# srio register map
Vendor: Texas Instruments
Peripheral module from a debugger description file (folder Keystone2).
Registers are 32-bit, read-write, no defined reset value unless marked. A register's access mark holds for its fields unless they carry their own. Offsets are as the file gives them; lines under a group give offsets from that group; [hi:lo] are bit positions; {n}, {i} and the like mark numbered series; 'fields as' and 'values as' point back to an identical list; <NAME> marks a mode.

## SRIO
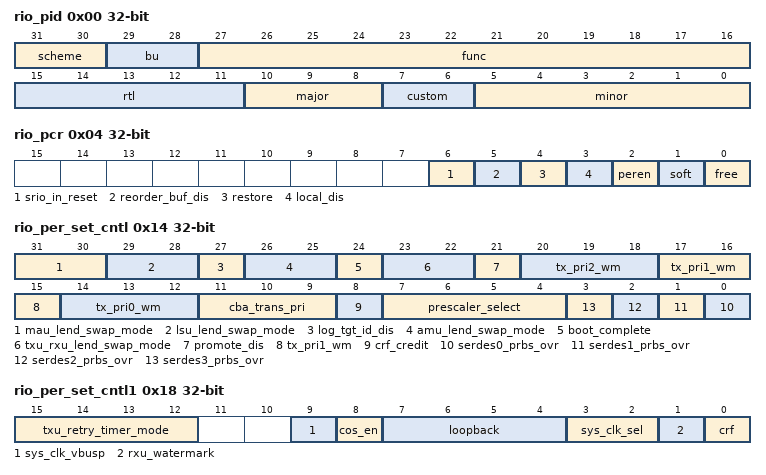
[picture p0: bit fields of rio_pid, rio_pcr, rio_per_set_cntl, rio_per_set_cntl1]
0x00 rio_pid ro
  [31:30] scheme — Reserved
  [29:28] bu — Business unit
  [27:16] func — Function ID
  [15:11] rtl — RTL revision
  [10:8] major — Major revision
  [7:6] custom
  [5:0] minor — Minor revision
0x04 rio_pcr access per field
  [6] srio_in_reset ro — SRIO has been given a reset isolation request, but has still not reached a stable state where it has started packet forwarding.
  [5] reorder_buf_dis rw — Write 1 disables the reorder bridge
  [4] restore rw — Write 1 clears local_dis
  [3] local_dis ro — local disable
  [2] peren rw — Peripheral enable
  [1] soft rw — Emulation control soft bit
  [0] free rw — Emulation control free bit
0x14 rio_per_set_cntl
  [31:30] mau_lend_swap_mode — MAU little endian swapping mode
  [29:28] lsu_lend_swap_mode — LSU little endian swapping mode
  [27] log_tgt_id_dis — Logical target ID disable mode
  [26:25] amu_lend_swap_mode — AMU little endian swapping mode
  [24] boot_complete — Controls ability to write any register during initialization
  [23:22] txu_rxu_lend_swap_mode — TXU/RXU little endian swap mode
  [21] promote_dis — Disable automatic promotion
  [20:18] tx_pri2_wm — Transmit credit threshold
  [17:15] tx_pri1_wm — Transmit credit threshold
  [14:12] tx_pri0_wm — Transmit credit threshold
  [11:9] cba_trans_pri — VBUS transaction priority
  [8] crf_credit
  [7:4] prescaler_select — VBUS frequency prescaler
  [n] serdes{n}_prbs_ovr (n=0..3) — SerDes PRBS override
0x18 rio_per_set_cntl1
  [15:12] txu_retry_timer_mode — Defines the total number of times the 14bit Rety Timer can expire before TXU will discard the retry request
  [9] sys_clk_vbusp — 0 = Use SYS_CLK_SEL to define the clock source SYS_CLK, 1 = Use vbusp_clk as the clock source for SYS_CLK
  [8] cos_en — Class of service enable
  [7:4] loopback — Loopback transmit data to receive on the same port
  [3:2] sys_clk_sel — SYS_CLK select
  [1] rxu_watermark
  [0] crf — 0=On a response, CRF is the same as the incoming request, 1=On a response, CFR is always 1
0x24 rio_gbl_en
  [0] en — global reset
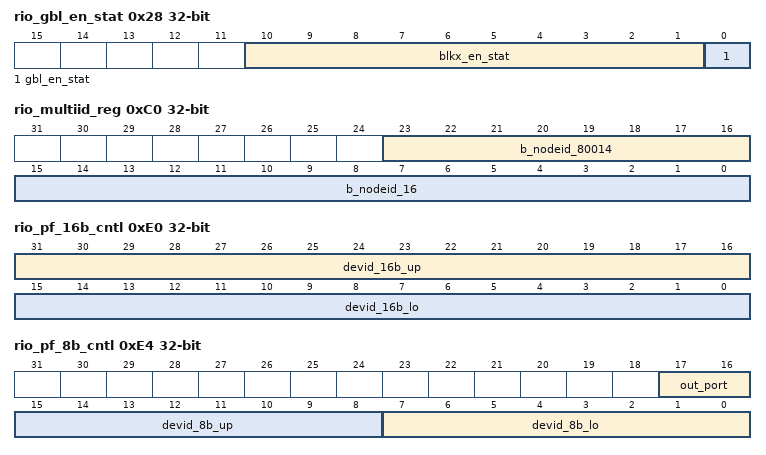
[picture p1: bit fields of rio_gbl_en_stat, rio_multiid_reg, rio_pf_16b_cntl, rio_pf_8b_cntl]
0x28 rio_gbl_en_stat ro
  [10:1] blkx_en_stat — Global enable status block 0..9
  [0] gbl_en_stat — Peripheral global enable status
0x2C rio_blk_en — (1 of 10, stride 8)
  [0] en — Block enable
0x30 rio_blk_en_stat ro — (1 of 10, stride 8)
  [0] en_status — Block enable status
0xC0 rio_multiid_reg — (1 of 8, stride 4)
  [23:16] b_nodeid_80014 — Secondary supported device ID check
  [15:0] b_nodeid_16 — Secondary supported device ID check
0xE0 rio_pf_16b_cntl — (1 of 8, stride 8)
  [31:16] devid_16b_up — Upper 16b DeviceID boundary
  [15:0] devid_16b_lo — Lower 16b DeviceID boundary
0xE4 rio_pf_8b_cntl — (1 of 8, stride 8)
  [17:16] out_port — Output port number for packets whose DestID falls within the 8b or 16b range for this table entry
  [15:8] devid_8b_up — Upper 8b DeviceID boundary
  [7:0] devid_8b_lo — Lower 8b DeviceID boundary
0x180 rio_doorbell_icsr — (1 of 4, stride 16)
  [15:0] rio_doorbell — ICS0 to ICS15
0x188 rio_doorbell_iccr wo — (1 of 4, stride 16)
  [15:0] rio_doorbell — ICC0 to ICC15
0x1C0 rio_lsu_icsr — (1 of 2, stride 16)
  [31:0] rio_lsu_icsr — LSU0 and LSU1 ICSR0-ICSR31
0x1C8 rio_lsu_iccr wo — (1 of 2, stride 16)
  [31:0] rio_lsu_iccr — LSU0 and LSU1 ICCR0-ICCR31
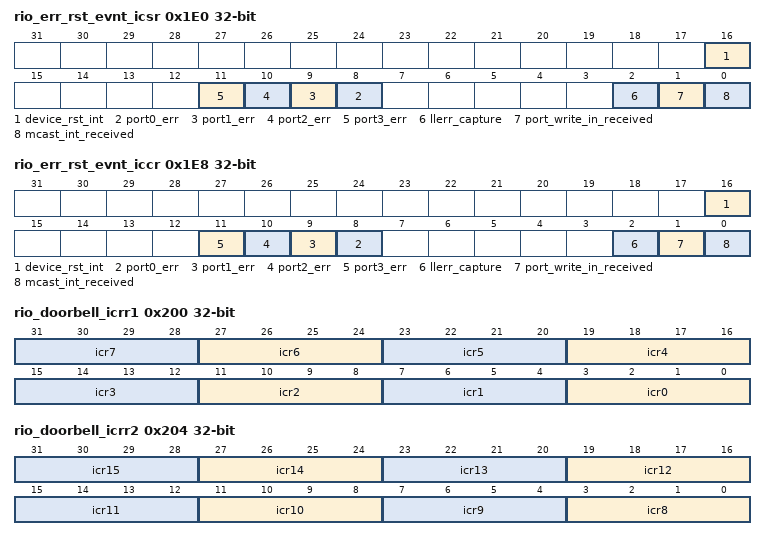
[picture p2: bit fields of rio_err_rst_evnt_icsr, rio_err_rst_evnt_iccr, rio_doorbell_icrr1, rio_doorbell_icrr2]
0x1E0 rio_err_rst_evnt_icsr
  [16] device_rst_int — Device reset interrupt from any port
  [n+8] port{n}_err (n=0..3) — Port {n} error
  [2] llerr_capture — Logical layer error management event capture
  [1] port_write_in_received — Port write in request received on any port
  [0] mcast_int_received — Multicast event control symbol interrupt received on any port
0x1E8 rio_err_rst_evnt_iccr wo
  fields as rio_err_rst_evnt_icsr
0x1F0 rio_amu_icsr
  [15:0] cprivid — CPRIVID0..15
0x1F8 rio_amu_iccr wo
  [15:0] cprivid — CPRIVID0..15
0x200 rio_doorbell_icrr1 — (1 of 4, stride 12)
  [4n+3:4n] icr{n} (n=0..7)
0x204 rio_doorbell_icrr2 — (1 of 4, stride 12)
  [4n-29:4n-32] icr{n} (n=8..15)
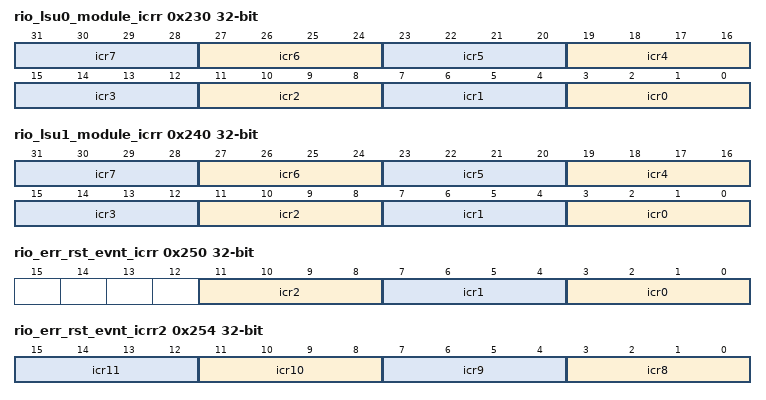
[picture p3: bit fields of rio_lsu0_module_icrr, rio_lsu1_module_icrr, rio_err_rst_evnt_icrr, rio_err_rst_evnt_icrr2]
0x230 rio_lsu0_module_icrr — (1 of 4, stride 4)
  [4n+3:4n] icr{n} (n=0..7)
0x240 rio_lsu1_module_icrr
  [4n+3:4n] icr{n} (n=0..7)
0x250 rio_err_rst_evnt_icrr
  [11:8] icr2, [7:4] icr1, [3:0] icr0
0x254 rio_err_rst_evnt_icrr2
  [4n-29:4n-32] icr{n} (n=8..11)
0x258 rio_err_rst_evnt_icrr3
  [3:0] icr16
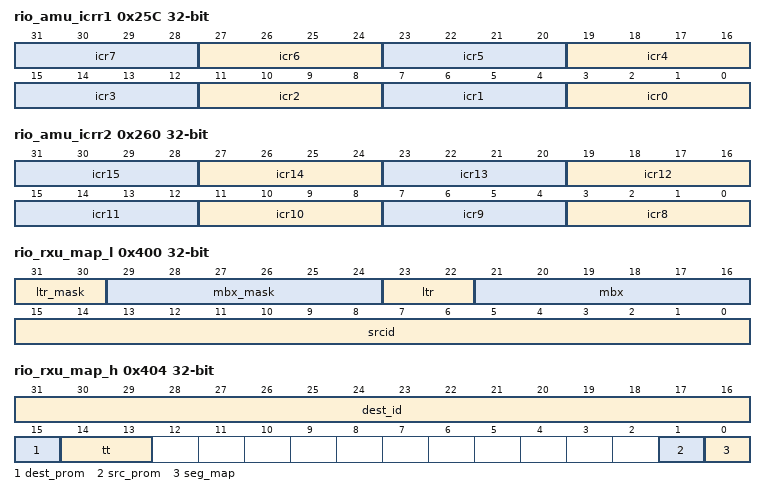
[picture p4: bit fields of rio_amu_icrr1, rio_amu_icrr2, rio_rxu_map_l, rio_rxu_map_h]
0x25C rio_amu_icrr1
  [4n+3:4n] icr{n} (n=0..7)
0x260 rio_amu_icrr2
  [4n-29:4n-32] icr{n} (n=8..15)
0x264 rio_interrupt_ctl
  [0] dbll_route — Doorbell interrupts routing table select
0x270 rio_intdst_decode ro — (1 of 24, stride 4)
  [31:0] isdr — Interrupt status decode bit 0..31
0x2D0 rio_intdst_rate_cnt — (1 of 16, stride 4)
  [31:0] count_down_value — INTDST rate control count down value
0x310 rio_intdst_rate_dis
  [15:0] raten_dis — Rate0..15 disable
0x400 rio_rxu_map_l — (1 of 64, stride 12)
  [31:30] ltr_mask — Mask bits for letter comparison
  [29:24] mbx_mask — Mask bits for mailbox comparison
  [23:22] ltr — Letter field
  [21:16] mbx — Mailbox field
  [15:0] srcid — Source ID
0x404 rio_rxu_map_h — (1 of 64, stride 12)
  [31:16] dest_id — Destination ID
  [15] dest_prom — Destination promiscuious bit
  [14:13] tt — Transaction type
  [1] src_prom — Source promiscuious bit
  [0] seg_map — Segment mapping
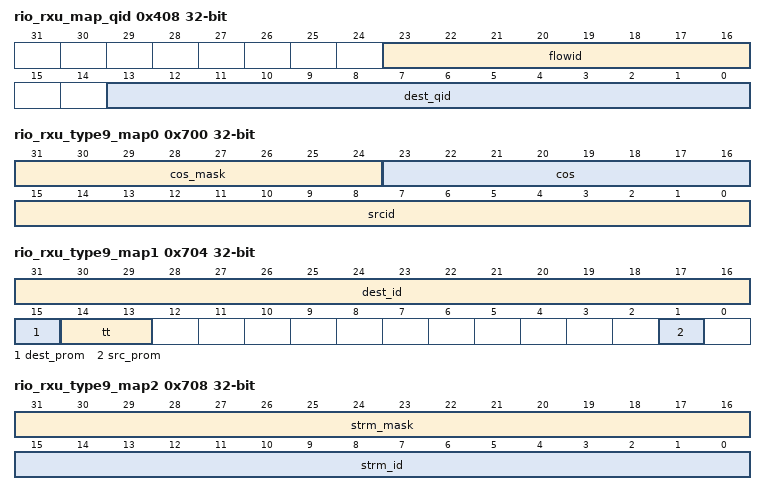
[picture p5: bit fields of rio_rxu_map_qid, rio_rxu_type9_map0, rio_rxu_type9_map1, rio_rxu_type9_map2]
0x408 rio_rxu_map_qid — (1 of 64, stride 12)
  [23:16] flowid
  [13:0] dest_qid — Destination queue ID
0x700 rio_rxu_type9_map0 — (1 of 64, stride 12)
  [31:24] cos_mask — Class of service mask
  [23:16] cos — Class of service
  [15:0] srcid — Source ID
0x704 rio_rxu_type9_map1 — (1 of 64, stride 12)
  [31:16] dest_id — Destination ID
  [15] dest_prom — Destination promiscuious bit
  [14:13] tt — Transaction type
  [1] src_prom — Source promiscuious bit
0x708 rio_rxu_type9_map2 — (1 of 64, stride 12)
  [31:16] strm_mask — Mask bits for StreamID comparision
  [15:0] strm_id — Stream ID
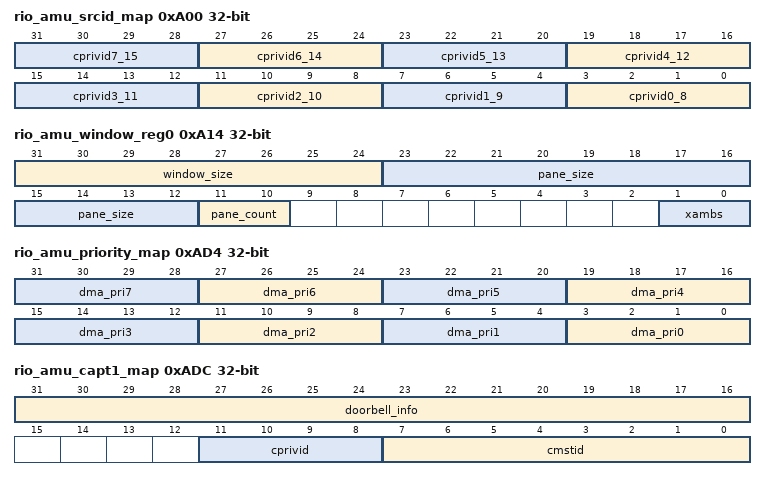
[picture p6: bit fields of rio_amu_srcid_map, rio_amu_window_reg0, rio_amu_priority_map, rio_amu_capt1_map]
0xA00 rio_amu_srcid_map — (1 of 4, stride 4)
  [4n+3:4n] cprivid{n}_{n+8} (n=0..7)
0xA14 rio_amu_window_reg0 access per field — (1 of 16, stride 12)
  [31:24] window_size ro
  [23:12] pane_size ro
  [11:10] pane_count rw — Pane count for associated window
  [1:0] xambs rw — RIO xambs field
0xA18 rio_amu_window_reg1 — (1 of 16, stride 12)
  [31:0] rio_address_msb
0xA1C rio_amu_window_reg2 — (1 of 16, stride 12)
  [31:0] rio_address_lsb
0xAD4 rio_amu_priority_map
  [4n+3:4n] dma_pri{n} (n=0..7) — DMA priority {n}
0xAD8 rio_amu_capt0_map
  [31:0] trans_address — transaction address
0xADC rio_amu_capt1_map access per field
  [31:16] doorbell_info ro — Doorbell information
  [11:8] cprivid rw
  [7:0] cmstid rw
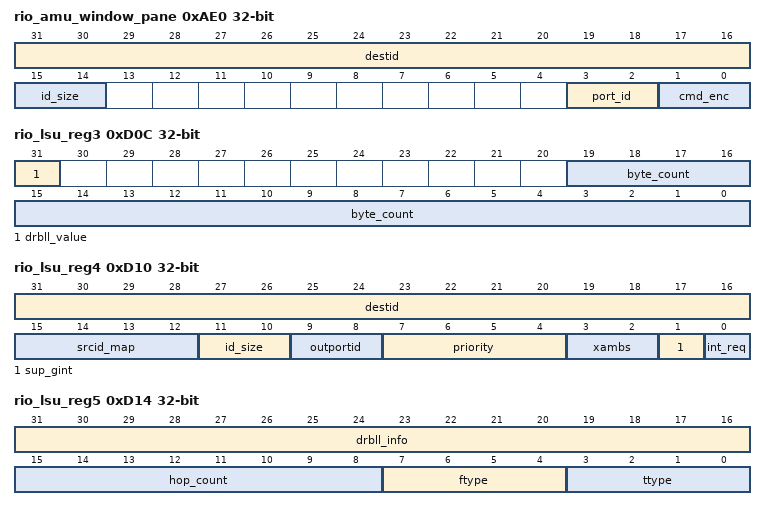
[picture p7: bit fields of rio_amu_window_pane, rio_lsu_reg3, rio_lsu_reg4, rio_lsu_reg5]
0xAE0 rio_amu_window_pane — (1 of 128, stride 4)
  [31:16] destid — RIO destination ID
  [15:14] id_size — Device ID size
  [3:2] port_id
  [1:0] cmd_enc — RIO transaction type
0xCE0 rio_amu_flow_masks0
  [15:0] amu_flow_mask — RIO AMU flow mask
0xD00 rio_lsu_reg0 — (1 of 8, stride 28)
  [31:0] rio_address_msb
0xD04 rio_lsu_reg1 — (1 of 8, stride 28)
  [31:0] rio_address_lsb — RIO address lsb/configuration offset
0xD08 rio_lsu_reg2 — (1 of 8, stride 28)
  [31:0] dsp_address
0xD0C rio_lsu_reg3 — (1 of 8, stride 28)
  [31] drbll_value — Doorbell value
  [19:0] byte_count
0xD10 rio_lsu_reg4 — (1 of 8, stride 28)
  [31:16] destid — Destination ID
  [15:12] srcid_map — Source ID
  [11:10] id_size
  [9:8] outportid — Output port ID
  [7:4] priority
  [3:2] xambs
  [1] sup_gint — Supress good interrupt
  [0] int_req — Interrupt request
0xD14 rio_lsu_reg5 — (1 of 8, stride 28)
  [31:16] drbll_info — Doorbell info
  [15:8] hop_count — RIO hop count field
  [7:4] ftype — Ftype field for all transactions
  [3:0] ttype — Transaction field
0xD18 rio_lsu_reg6 access per field — (1 of 8, stride 28)
  [31] busy ro — Command register status
  [30] full ro — All shadow registers are in use
  [31:28] privid wo
  [27] cbusy wo — Clear busy bit
  [4] lcb ro — LSU context bit
  [5:2] scrid_map wo — Shadow register source ID bit
  [1] restart wo — Restart bit
  [3:0] ltid ro — LSU transaction index
  [0] flush wo — Flush bit
0xDE0 rio_lsu_setup_reg0 access per field
  [4n+3:4n] lsu{n}_cnt ro (n=0..7) — LSU{n} count
  [20:16] shadow_grp1 wo — Shadow registers associated with all the LSU 4-7
  [4:0] shadow_grp0 wo — Shadow registers associated with all the LSU 0-3
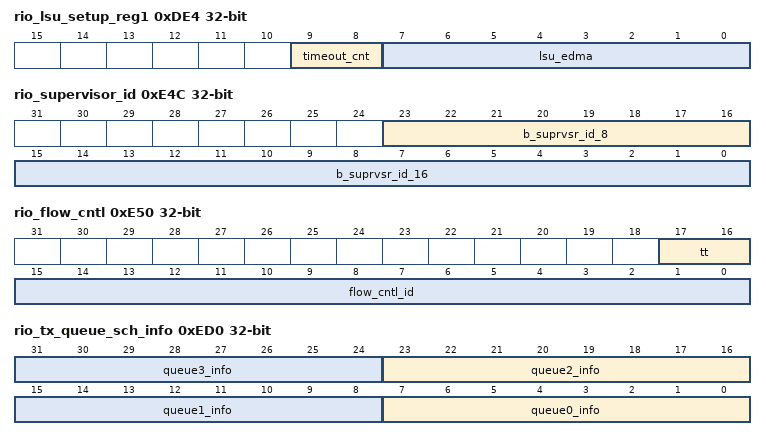
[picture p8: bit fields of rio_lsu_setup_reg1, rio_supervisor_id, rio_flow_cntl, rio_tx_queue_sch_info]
0xDE4 rio_lsu_setup_reg1
  [9:8] timeout_cnt — Timeout count
  [7:0] lsu_edma — LSU0..7 edma
0xDE8 lsu_stat_reg — (1 of 6, stride 4)
  [31:0] lsuX_stat — LSU stat
0xE00 rio_lsu_flow_masks — (1 of 4, stride 4)
  [31:0] lsu_flow_mask — LSU flow masks
0xE4C rio_supervisor_id
  [23:16] b_suprvsr_id_8 — 8b supervisor ID
  [15:0] b_suprvsr_id_16 — 16b supervisor ID
0xE50 rio_flow_cntl — (1 of 16, stride 4)
  [17:16] tt — Selects flow control ID length
  [15:0] flow_cntl_id — Flow control ID
0xEB0 rio_tx_cppi_flow_masks — (1 of 8, stride 4)
  [31:0] tx_queue_flow_mask — Transmit CPPI flow masks
0xED0 rio_tx_queue_sch_info — (1 of 4, stride 4)
  [8n+7:8n] queue{n}_info (n=0..3) — Queues {n} {n+4} {n+8} {n+12} info
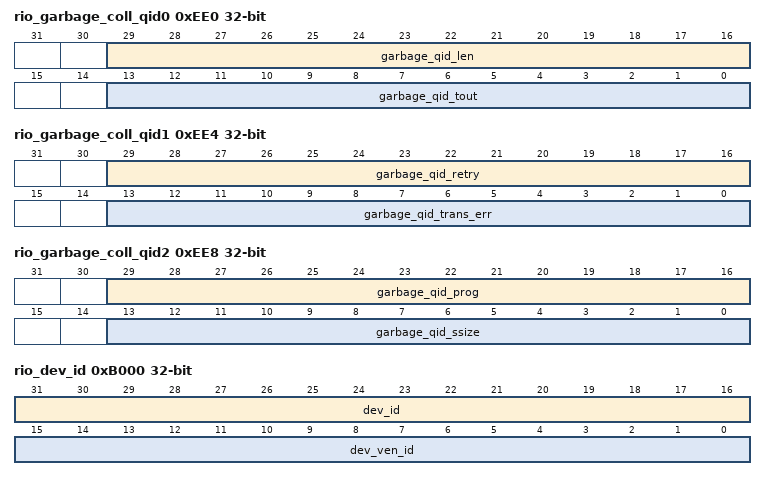
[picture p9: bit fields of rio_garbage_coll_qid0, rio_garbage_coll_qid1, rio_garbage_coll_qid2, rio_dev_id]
0xEE0 rio_garbage_coll_qid0
  [29:16] garbage_qid_len — Garbage length mismatch
  [13:0] garbage_qid_tout — Garbage timeout
0xEE4 rio_garbage_coll_qid1
  [29:16] garbage_qid_retry — Garbage excessive retries
  [13:0] garbage_qid_trans_err — Garbage transaction error
0xEE8 rio_garbage_coll_qid2
  [29:16] garbage_qid_prog — Garbage queue for identifying all programming errors
  [13:0] garbage_qid_ssize — Garbage ssize
0xB000 rio_dev_id
  [31:16] dev_id — Device ID
  [15:0] dev_ven_id — Device vendor ID
0xB004 rio_dev_info
  [31:0] device_rev — Device revision level
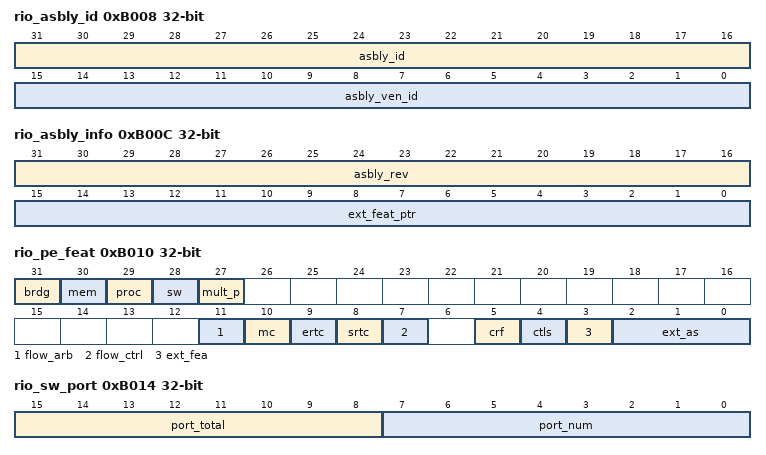
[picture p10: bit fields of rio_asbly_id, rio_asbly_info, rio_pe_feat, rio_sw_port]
0xB008 rio_asbly_id
  [31:16] asbly_id — Assembly ID
  [15:0] asbly_ven_id — Assembly vendor ID
0xB00C rio_asbly_info
  [31:16] asbly_rev — Assembly revision level
  [15:0] ext_feat_ptr — Extended features pointer
0xB010 rio_pe_feat
  [31] brdg — Bridge
  [30] mem — Memory
  [29] proc — Processor
  [28] sw — Switching capabilities
  [27] mult_p — Multiport
  [11] flow_arb — Flow arbitration support
  [10] mc — Multicast
  [9] ertc — Extended route table configuration support
  [8] srtc — Standard route table configuration support
  [7] flow_ctrl — Flow control support
  [5] crf — Critical request flow support
  [4] ctls — Common transport large system support
  [3] ext_fea — Extended features pointer is valid
  [2:0] ext_as — Extended addressing support
0xB014 rio_sw_port ro
  [15:8] port_total
  [7:0] port_num — Port number
0xB018 rio_src_op
  [31] g_read — Supports GSM read operation
  [30] g_iread — Supports GSM instruction read operation
  [29] g_read_own — Supports GSM read-for-ownership operation
  [28] g_dc_invalidate — Supports GSM data cache invalidate operation
  [27] g_castout — Supports GSM castout operation
  [26] g_dc_flush — Supports GSM data cache flush
  [25] g_io_read — Supports GSM I/O read operation
  [24] g_ic_invalidate — Supports GSM instruction cache invalidate operation
  [23] g_tlb_invalidate — Supports GSM TLB invalidate-entry operation
  [22] g_tlb_sync — Supports GSM TLB invalidate entry sync operation
  [21] g_rio_rsvd_10 — This field is reserved by the RapidIO Interconnect Specification
  [20] g_rio_rsvd_11 — This field is reserved by the RapidIO Interconnect Specification
  [19] ds_tm — Supports data streaming traffic management
  [18] ds — Supports data streaming
  [17:16] implement_def — Implementation defined
  [15] read — Supports read operation
  [14] write — Supports write operation
  [13] strm_wr — Supports streaming write operation
  [12] wr_res — Supports write-with-response operation
  [11] d_msg — Supports data messaging
  [10] dbell — Supports doorbell
  [9] acswap — Supports atomic (compare-and-swap) operation
  [8] atswap — Supports atomic (test-and-swap) operation
  [7] a_inc — Supports atomic (increment) operation
  [6] a_dec — Supports atomic (decrement) operation
  [5] a_set — Supports atomic (set) operation
  [4] a_clear — Supports atomic (clear) operation
  [34:3] a_swap — Supports atomic (swap) operation
  [2] port_wr — Supports port-write operation
  [1:0] implement_def2 — Implementation defined
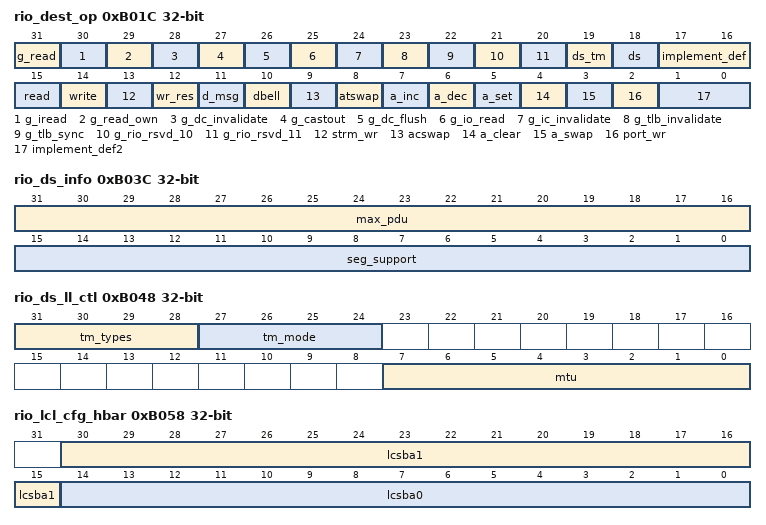
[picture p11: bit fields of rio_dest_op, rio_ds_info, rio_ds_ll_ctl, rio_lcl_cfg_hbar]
0xB01C rio_dest_op
  [31] g_read — Supports GSM read operation
  [30] g_iread — Supports GSM instruction read operation
  [29] g_read_own — Supports GSM read-for-ownership operation
  [28] g_dc_invalidate — Supports GSM data cache invalidate operation
  [27] g_castout — Supports GSM castout operation
  [26] g_dc_flush — Supports GSM data cache flush
  [25] g_io_read — Supports GSM I/O read operation
  [24] g_ic_invalidate — Supports GSM instruction cache invalidate operation
  [23] g_tlb_invalidate — Supports GSM TLB invalidate-entry operation
  [22] g_tlb_sync — Supports GSM TLB invalidate entry sync operation
  [21] g_rio_rsvd_10 — This field is reserved by the RapidIO Interconnect Specification
  [20] g_rio_rsvd_11 — This field is reserved by the RapidIO Interconnect Specification
  [19] ds_tm — Supports data streaming traffic management
  [18] ds — Supports data streaming
  [17:16] implement_def — Implementation defined
  [15] read — Supports read operation
  [14] write — Supports write operation
  [13] strm_wr — Supports streaming write operation
  [12] wr_res — Supports write-with-response operation
  [11] d_msg — Supports data messaging
  [10] dbell — Supports doorbell
  [9] acswap — Supports atomic (compare-and-swap) operation
  [8] atswap — Supports atomic (test-and-swap) operation
  [7] a_inc — Supports atomic (increment) operation
  [6] a_dec — Supports atomic (decrement) operation
  [5] a_set — Supports atomic (set) operation
  [4] a_clear — Supports atomic (clear) operation
  [3] a_swap — Supports atomic (swap) operation
  [2] port_wr — Supports port-write operation
  [1:0] implement_def2 — Implementation defined
0xB03C rio_ds_info ro
  [31:16] max_pdu — The maximum PDU size in bytes supported by the destination end point
  [15:0] seg_support — The number of segmentation contexts supported by the destination endpoint
0xB048 rio_ds_ll_ctl access per field
  [31:28] tm_types ro — Traffic management types supported
  [27:24] tm_mode rw — Traffic management mode of operation
  [7:0] mtu ro — Maximum transmission unit
0xB04C rio_pe_ll_ctl
  [2:0] ext_addr_ctl — Controls the number of address bits generated by the PE as a source and processed by the PE as the target of an operation
0xB058 rio_lcl_cfg_hbar
  [30:15] lcsba1 — See RapidIO spec 4.5.3
  [14:0] lcsba0 — See RapidIO spec 4.5.3
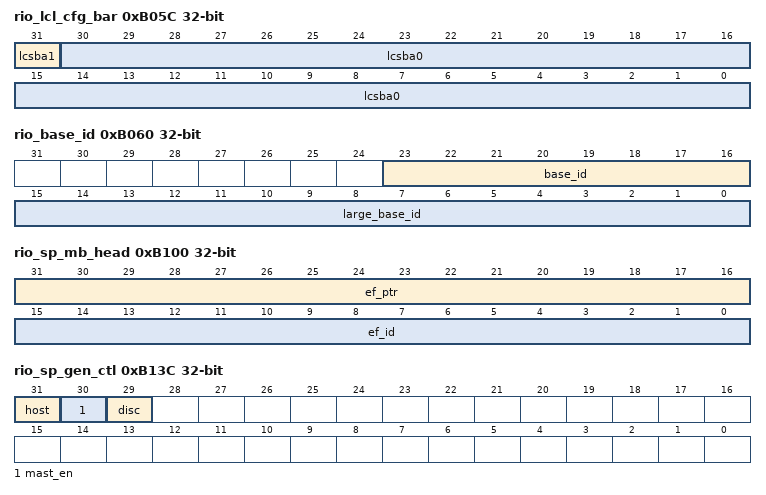
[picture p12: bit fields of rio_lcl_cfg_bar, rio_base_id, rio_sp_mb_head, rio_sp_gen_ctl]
0xB05C rio_lcl_cfg_bar
  [31] lcsba1 — See RapidIO spec 4.5.3
  [30:0] lcsba0 — See RapidIO spec 4.5.3
0xB060 rio_base_id
  [23:16] base_id — Base ID of device in small common transport system
  [15:0] large_base_id — Base ID of device in large common transport system
0xB068 rio_host_base_id_lock
  [15:0] host_base_id — Base ID for the device initializing endpoint
0xB06C rio_comp_tag
  [31:0] ctag — Component tag
0xB100 rio_sp_mb_head ro
  [31:16] ef_ptr — Extended features pointer
  [15:0] ef_id — Hard-wired extended features ID
0xB120 rio_sp_lt_ctl
  [31:8] tval — Timeout interval value
0xB124 rio_sp_rt_ctl
  [31:8] tval — Timeout interval value
0xB13C rio_sp_gen_ctl
  [31] host — Host devices
  [30] mast_en — Master Enable
  [29] disc — Discovered
0xB140 rio_sp_lm_req — (1 of 4, stride 32)
  [2:0] cmd — Command
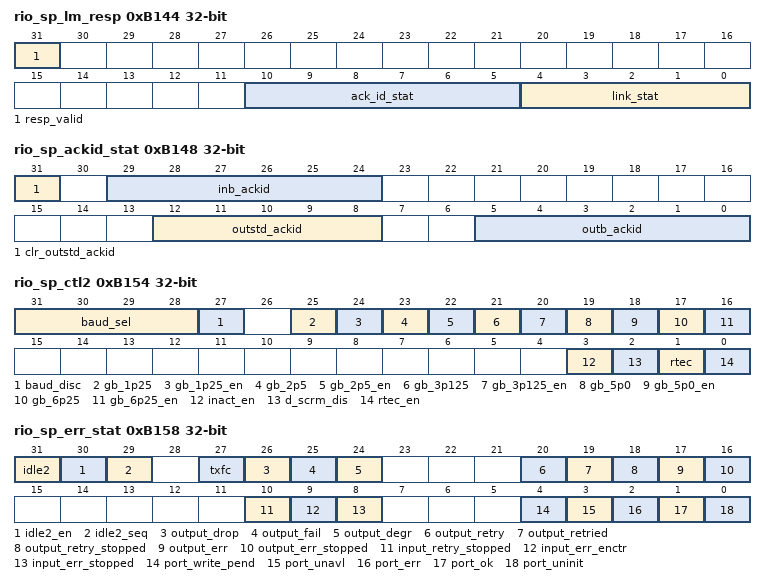
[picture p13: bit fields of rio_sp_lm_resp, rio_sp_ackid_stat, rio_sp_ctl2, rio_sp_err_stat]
0xB144 rio_sp_lm_resp ro — (1 of 4, stride 32)
  [31] resp_valid — Response valid
  [10:5] ack_id_stat — AckID status field
  [4:0] link_stat — Link status field
0xB148 rio_sp_ackid_stat access per field — (1 of 4, stride 32)
  [31] clr_outstd_ackid rw — Discard all outstanding unack packets
  [29:24] inb_ackid rw — Inbound ack ID
  [12:8] outstd_ackid ro — Outstanding ack ID
  [5:0] outb_ackid rw — Outbound ack ID
0xB154 rio_sp_ctl2 access per field — (1 of 4, stride 32)
  [31:28] baud_sel ro — Baud rate indicator
  [27] baud_disc ro — Support baud rate discovery
  [25] gb_1p25 ro — Support 1.25 Gbaud
  [24] gb_1p25_en rw — 1.25 Gbaud enable
  [23] gb_2p5 ro — Support 2.25 Gbaud
  [22] gb_2p5_en rw — 2.25 Gbaud enable
  [21] gb_3p125 ro — Support 3.25 Gbaud
  [20] gb_3p125_en rw — 3.25 Gbaud enable
  [19] gb_5p0 ro — Support 5.25 Gbaud
  [18] gb_5p0_en rw — Gbaud 5.25 enable
  [17] gb_6p25 ro — Support 6.25 Gbaud
  [16] gb_6p25_en rw — 6.25 Gbaud enable
  [3] inact_en rw — Inactivity enable
  [2] d_scrm_dis rw — Data de-scrambler disable
  [1] rtec ro — Remote transmit emphasis control
  [0] rtec_en ro — Remote transmit emphasis control enable
0xB158 rio_sp_err_stat access per field — (1 of 4, stride 32)
  [31] idle2 ro — Support idle sequence 2
  [30] idle2_en ro — Idle sequence 2 enable
  [29] idle2_seq ro — Idle sequence active
  [27] txfc ro — Transmitter/Receiver flow control
  [26] output_drop wo — Output port dropped packet
  [25] output_fail wo — Output failed encountered
  [24] output_degr wo — Output degraded encountered
  [20] output_retry wo — Output retry encountered
  [19] output_retried ro
  [18] output_retry_stopped ro
  [17] output_err wo — Output error encountered
  [16] output_err_stopped ro — Output error stopped
  [10] input_retry_stopped ro
  [9] input_err_enctr wo — Input error encountered
  [8] input_err_stopped ro — Input error stopped
  [4] port_write_pend wo — Port write pending
  [3] port_unavl ro — Port unavailable
  [2] port_err wo — Port error
  [1] port_ok ro
  [0] port_uninit ro — Port uninitialized
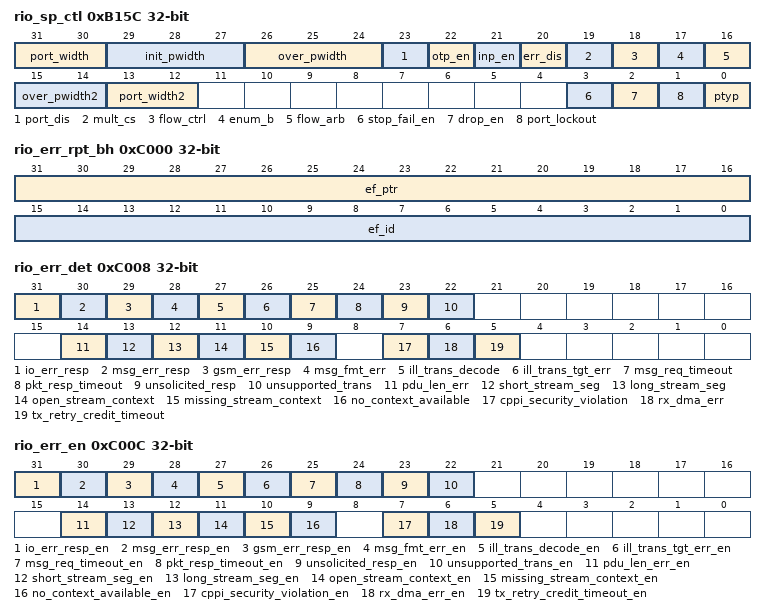
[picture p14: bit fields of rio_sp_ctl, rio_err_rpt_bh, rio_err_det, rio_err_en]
0xB15C rio_sp_ctl access per field — (1 of 4, stride 32)
  [31:30] port_width ro — Port widths supported
  [29:27] init_pwidth ro — Initialized port width
  [26:24] over_pwidth rw — Port width override
  [23] port_dis rw — Port disable
  [22] otp_en rw — Output port transmit enable
  [21] inp_en rw — Inbound port enable
  [20] err_dis rw — Error checking disable
  [19] mult_cs rw — Multicast event control symbols send
  [18] flow_ctrl rw — Enable flow control transactions
  [17] enum_b rw — Enumeration boundary bit
  [16] flow_arb rw — Enable flow arbitration transactions
  [15:14] over_pwidth2 ro — Override port width 2
  [13:12] port_width2 ro
  [3] stop_fail_en rw — Stop failed enable
  [2] drop_en rw — Drop packet enable
  [1] port_lockout rw
  [0] ptyp ro — Port type
0xC000 rio_err_rpt_bh ro
  [31:16] ef_ptr — Extended features pointer
  [15:0] ef_id — Extended features ID
0xC008 rio_err_det access per field
  [31] io_err_resp rw — Received a response of ERROR for an IO Logical Layer Request
  [30] msg_err_resp rw — Received a response of ERROR for an MSG Logical Layer Request
  [29] gsm_err_resp ro — Received a response of ERROR for an GSM Logical Layer Request
  [28] msg_fmt_err rw — Received MESSAGE packet data payload with an invalid size or segment (MSG logical)
  [27] ill_trans_decode rw — Received illegal fields in the request/response packet for a supported transaction (IO/MSG/GSM logical)
  [26] ill_trans_tgt_err ro — Received a packet that contained a destination ID that is not defined for this end point
  [25] msg_req_timeout rw — A required message request has not been received within the specified time-out interval (MSG logical)
  [24] pkt_resp_timeout rw — A required response has not been received within the specified timeout interval (IO/MSG/GSM logical)
  [23] unsolicited_resp rw — An unsolicited/unexpected Response packet was received (IO/MSG/GSM logical; only Maintenance response for switches)
  [22] unsupported_trans rw — A transaction is received that is not supported in the Destination Operations CAR (IO/MSG/GSM logical; only Maintenance port-write for switches)
  [14] pdu_len_err rw — The length of a reassembled PDU differs from the PDU length
  [13] short_stream_seg rw — Received a start or continuation data streaming segment with a payload size less than that the MTU
  [12] long_stream_seg rw — Received a data streaming segment with a payload size greater than the MTU
  [11] open_stream_context rw — A start or single data streaming segment was received for an already open segmentation context
  [10] missing_stream_context rw — A continuation or end data streaming segment was received for a closed or non-existent segmentation context
  [9] no_context_available rw — No context available for type9 traffic causing the packet to be dropped
  [7] cppi_security_violation rw — Access to one of the RX queues was blocked and mapping was not possible
  [6] rx_dma_err rw — DMA access to MAU was blocked
  [5] tx_retry_credit_timeout rw — If the TXU does not get credit for a retry packet, and times out, this error bit will be set
0xC00C rio_err_en
  [31] io_err_resp_en — Enable reporting of an IO error response
  [30] msg_err_resp_en — Enable reporting of a Message error response
  [29] gsm_err_resp_en — Enable reporting of a GSM error response
  [28] msg_fmt_err_en — Enable reporting of a message format error
  [27] ill_trans_decode_en — Enable reporting of an illegal transaction decode error
  [26] ill_trans_tgt_err_en — Enable reporting of an illegal transaction target error
  [25] msg_req_timeout_en — Enable reporting of a Message Request time-out error
  [24] pkt_resp_timeout_en — Enable reporting of a packet response time-out error
  [23] unsolicited_resp_en — Enable reporting of an unsolicited response error
  [22] unsupported_trans_en — Enable reporting of an unsupported transaction error
  [14] pdu_len_err_en — Enable reporting of a reassembled PDU length that differs from the PDU length carried in the end data streaming segment packet header
  [13] short_stream_seg_en — Enable reporting of a start or continuation data streaming segment received with a payload size less that the MTU
  [12] long_stream_seg_en — Enable reporting of a any data streaming segment received with a payload size greater then the MTU
  [11] open_stream_context_en — Enable reporting of a start or single data streaming segment received for an already open segmentation context
  [10] missing_stream_context_en — Enable reporting of a continuation or end data streaming segment received for a closed or non-existent segmentation context
  [9] no_context_available_en — Enable reporting of no context available for type9 traffic causing the packet to be dropped
  [7] cppi_security_violation_en — Enable reporting of attempt at unauthorized access to a RX queue
  [6] rx_dma_err_en — Enable reporting of attempt at unauthorized memory location access
  [5] tx_retry_credit_timeout_en — Enable reporting of if the TXU does not get credit for a retry packet, and times out, this error bit will be set
0xC010 rio_h_addr_capt
  [31:0] addr_high — Most Significant 32 bits of the address associated with the error
0xC014 rio_addr_capt
  [31:3] addr_low — Least Significant 29 bits of the address associated with the error
  [1:0] xamsbs — Extended address bits of the address associated with the error
0xC018 rio_id_capt
  [31:24] msb_dstid — Most significant byte of the destinationID associated with the error
  [23:16] dstid — The destinationID associated with the error
  [15:8] msb_srctid — Most significant byte of the sourceID associated with the error
  [7:0] srcid — The sourceID associated with the error
0xC01C rio_ctrl_capt
  [31:28] ftype — Format type associated with the error
  [27:24] ttype — Transaction type associated with the error
  [23:16] msg_info — Letter, mbox, and msgseg for the last message request received for the mailbox that had an error
  [15:0] imp_specific — Implementation specific information associated with the error
0xC028 rio_pw_tgt_id
  [31:24] deviceid_msb — MSB of the port-write target deviceID
  [23:16] deviceid — Port-write target deviceID
  [15] id_large — ID size for port write
0xC040 rio_sp_err_det access per field — (1 of 4, stride 64)
  [31] imp_spec rw — Error implementation specific information
  [22] cs_crc_err ro — Received control symbol with bad CRC
  [21] cs_ill_id rw — Received ack control symbol with unexpected ack ID
  [20] cs_not_acc rw — Received packet not accepted control symbol
  [19] pkt_ill_ackid rw — Received packet with unexpected ack ID
  [18] pkt_crc_err rw — Received packet with bad CRC
  [17] pkt_ill_size rw — Received packet exceeds 276 bytes
  [14] dscram_los rw — Loss of descrambler synchronization
  [5] lr_ackid_ill rw — Non-outstanding link response ack ID received
  [4] prot_err rw — Unexpected protocol error received
  [2] delin_err ro — Delineation error received
  [1] cs_ack_ill rw — Unexpected ack control symbol received
  [0] link_to rw — Link timeout
0xC044 rio_sp_rate_en — (1 of 4, stride 64)
  [31] imp_spec_en — Implementation on specific error enable
  [22] cs_crc_en — Received control symbol with bad crc enable
  [21] cs_ill_id_en — Received ack control symbol with unexpected ack ID enable
  [20] cs_not_acc_en — Received packet not accepted control symbol enable
  [19] pkt_ill_ackid_en — Received packet not unexpected ackID
  [18] pkt_crc_err_en — Received packet with bad CRC enable
  [17] pkt_ill_size_en — Received packet exceeds 276 bytes enable
  [14] dscram_los_en — Loss of descrambler synchronization enable
  [5] lr_ackid_ill_en — Non-outstanding link response ackID enable
  [4] prot_err_en — Error rate counting of protocol errors enable
  [2] delin_err_en — Error rate counting of delineation errors enable
  [1] cs_ack_ill_en — Received unexpected ack control symbol enable
  [0] link_to_en — Link timeout enable
0xC048 rio_sp_err_attr_capt — (1 of 4, stride 64)
  [31:29] info_type — Type of Information logged
  [28:24] err_type — Error type
  [23:4] impl_dep — Implementation dependant error info
  [0] val_capt — Capture registers contain valid info
0xC04C rio_sp_err_capt_0 — (1 of 4, stride 64)
  [31:0] capt_0 — Character and control symbol or bytes 0 to 3 of packet header
{0xC04C+4i} rio_sp_err_capt_{i} (i=1..3) — (1 of 4, stride 64)
  [31:0] capt_{i} — Bytes {4i} to {4i+3} of packet header
0xC068 rio_sp_err_rate — (1 of 4, stride 64)
  [31:24] err_rb — Error rate bias
  [17:16] err_rr — Error rate recovery
  [15:8] err_peak — Peak error rate
  [7:0] err_rate_cnt — Error rate counter
0xC06C rio_sp_err_thresh — (1 of 4, stride 64)
  [31:24] err_rft — Error rate failed threshold trigger
  [23:16] err_rdt — Error rate degraded threshold trigger
0xE000 rio_per_lane_bh ro
  fields as rio_err_rpt_bh
0xE010 rio_lane_stat0 access per field — (1 of 4, stride 32)
  [31:24] port_num ro — Port number associated with this lane
  [23:20] lane_num ro — Lane within the port that this lane is associated with
  [19] tx_type rw — Transmitter type
  [18] tx_mode ro — Transmitter mode
  [17:16] rx_type rw — Receiver type
  [15] rx_inv ro — Receiver input inverted
  [14] rx_trn ro — Receiver trained
  [13] rx_sync ro — Receiver synchronization
  [12] rx_rdy ro — Receiver ready
  [11:8] err_cnt ro — Decoding error count
  [7] chg_sync ro — Change in RX_SYNC state
  [6] chg_trn ro — Change in RX_TRN value
  [3] stat1 rw — Stat1 register exists
  [2:0] stat2_7 rw — Stat2
0xE014 rio_lane_stat1 access per field — (1 of 4, stride 32)
  [31] idle2 wo — Indicates IDLE2 sequence received
  [30] info_ok ro — Indicates IDLE2 information current
  [29] chg ro — Other register bits changed
  [28] impl_spec ro — Implementation specific meaning
  [27] lp_rx_trn ro — Link partner receiver trained
  [26:24] lp_width ro — Link partner port width
  [23:20] lp_lane_num ro — Link partner lane number status
  [19:18] lp_tap_m1 ro — Link partner tap minus 1 status
  [17:16] lp_tap_p1 ro — Link partner tap plus 1 status
  [15] lp_scrm ro — Link partner data scramble/descramble setting
0x1B000 rio_plm_bh ro
  [31:16] next_blk_ptr — Pointer to the next register block
  [15:12] blk_rev — Block type revision
  [11:0] blk_type — Block type
0x1B080 rio_plm_sp_imp_spec_ctl — (1 of 4, stride 128)
  [31] payl_cap — Payload capture
  [30] use_idle2 — Allows use of the IDLE2 sequence below 5.5 Gbaud
  [29] use_idle1 — Allows use of the IDLE1 sequence above 5.5 Gbaud
  [28] dlb_en — Digital equipment loopback mode for port
  [26] force_reinit — Force Link Re-initialization Process
  [25] soft_rst_port — Software reset control for this port
  [24] tx_bypass — Bypass the transmitter clock crossing FIFO
  [23] llb_en — Line loopback mode for port
  [21] port_self_rst — Port self reset
  [20] self_rst — Self reset
  [19:18] swap_tx — Transmitter lane swap functionality
  [17:16] swap_rx — Receiver lane swap functionality
  [15:0] dlt_thresh — Sets threshold for the dead link timer
0x1B084 rio_plm_sp_pwdn_ctl — (1 of 4, stride 128)
  [0] pwdn_port — Power down port
0x1B090 rio_plm_sp_status access per field — (1 of 4, stride 128)
  [31] max_denial wo — Maximum denial error
  [28] link_init wo — Link initialization notification
  [27] dlt wo — Dead link timer event
  [26] port_err wo — Port error
  [25] output_fail wo
  [24] output_degr wo — Output degradation
  [16] rst_req wo — Inbound reset request received
  [15] pbm_pw ro — Physical buffer module detected a port-write
  [14] tlm_pw ro — Transport layer module detected a port-write
  [12] mecs wo — Inbound MECS received
  [11] pbm_int ro — Physical buffer module detected an interrupt
  [10] tlm_int ro — Transport layer module detected an interrupt
0x1B094 rio_plm_sp_int_enable — (1 of 4, stride 128)
  [31] max_denial — Maximum denial error enable
  [28] link_init — Link initialization notification enable
  [27] dlt — Dead link timer event enable
  [26] port_err — Port error enable
  [25] output_fail — Output fail enable
  [24] output_degr — Output degradation enable
0x1B098 rio_plm_sp_pw_enable — (1 of 4, stride 128)
  [31] max_denial — Port-write maximum denial error enable
  [28] link_init — Port-write link initialization notification enable
  [27] dlt — Port-write dead link timer event enable
  [26] port_err — Port-write port error enable
  [25] output_fail — Port-write output fail enable
  [24] output_degr — Port-write output degradation enable
0x1B09C rio_plm_sp_event_gen — (1 of 4, stride 128)
  [31] max_denial — Create maximum denial event
  [28] link_init — Create link initialization event
  [27] dlt — Create dead link timer event
  [26] port_err — Create port error event
  [25] output_fail — Create output fail event
  [24] output_degr — Create output degradation event
  [16] rst_req — Create inbound reset request
0x1B0A0 rio_plm_sp_all_int_en — (1 of 4, stride 128)
  [0] irq_en — Interrupt error reporting
0x1B0A4 rio_plm_sp_all_pw_en — (1 of 4, stride 128)
  [0] pw_en — Port-write error reporting enable
0x1B0B0 rio_plm_sp_path_ctl access per field — (1 of 4, stride 128)
  [20:16] path_id ro — Path in which this port resides
  [10:8] path_configuration ro
  [2:0] path_mode rw
0x1B0B4 rio_plm_sp_discovery_timer — (1 of 4, stride 128)
  [31:28] discovery_timer — Port 0
0x1B0B8 rio_plm_sp_silence_timer — (1 of 4, stride 128)
  [31:28] silence_timer
0x1B0BC rio_plm_sp_vmin_exp — (1 of 4, stride 128)
  [28:24] vmin_exp — Number of VALID code groups required for synchronization
  [19:16] imax — Maximum threshold for Icounter
  [11:8] mmax — Maximum threshold for Mcounter
0x1B0C0 rio_plm_sp_pol_ctl — (1 of 4, stride 128)
  [n+16] tx{n}_pol (n=0..3) — TX{n} polarity
  [n] rx{n}_pol (n=0..3) — RX{n} polarity
0x1B0C8 rio_plm_sp_denial_ctl — (1 of 4, stride 128)
  [29] cnt_pna — Packet-not-accepted control
  [28] cnt_rty — Count retry
  [7:0] denial_thresh — Denial threshold
0x1B0D0 rio_plm_sp_rcvd_mecs wo — (1 of 4, stride 128)
  [7:0] cmd_stat — MECS commands received
0x1B0D8 rio_plm_sp_mecs_fwd — (1 of 4, stride 128)
  [7:1] subscription — Specifies which MECS command values the port should forward to its link
  [0] mult_cs — This bit is mapped to RapidIO Port 0..3 Control CSR
0x1B0E0 rio_plm_sp_long_cs_tx1 — (1 of 4, stride 128)
  [30:28] stype_0 — Encoding for control symbol
  [25:20] par_0 — Used in conjunction with stype0 encoding
  [17:12] par_1 — Used in conjunction with stype0 encoding
  [8] cs_emb — Embed control symbol into data stream
  [6:4] stype_1 — Encoding for the control symbol that uses the CMD parameter
  [2:0] cmd — Used with stype1 encoding to define the link maintenance commands
0x1B0E4 rio_plm_sp_long_cs_tx2 — (1 of 4, stride 128)
  [30:28] stype_2 — Stype 2 encoding
  [26:16] parm — Used in conjunction with stype2 encoding
0x1B300 rio_tlm_bh ro
  [31:16] nxt_blk_ptr — Pointer to the next register block
  [15:12] blk_rev — Block type revision
  [11:0] blk_type — Block type
0x1B380 rio_tlm_sp_control access per field — (1 of 4, stride 128)
  [30] portgroup_select rw — Port group configurator
  [29:28] voq_select rw — VOQ configurator
  [21] tgt_id_dis rw — Promiscuous mode configurator used with mtc_tgt_id_dis
  [20] mtc_tgt_id_dis rw — Promiscuous mode configurator used with tgt_id_dis
  [15:12] length ro — Sets number of data nodes
0x1B390 rio_tlm_sp_status wo — (1 of 4, stride 128)
  [31] ig_bad_vc — Inbound packet with VC bit set
  [20] ig_brr_filter — Discarded inbound transaction based on BRR
0x1B394 rio_tlm_sp_int_enable — (1 of 4, stride 128)
  [31] ig_bad_vc — Enable ig_bad_vc to contribute to ports IRQ
  [20] ig_brr_filter — Enable ig_brr_filter to contribute to ports IRQ
0x1B398 rio_tlm_sp_pw_enable — (1 of 4, stride 128)
  [31] ig_bad_vc — Enable ig_bad_vc to contribute to port-write request
  [20] ig_brr_filter — Enable ig_brr_filter to contribute to port-write request
0x1B39C rio_tlm_sp_event_gen — (1 of 4, stride 128)
  [31] ig_bad_vc — Enable ig_bad_vc in port 0
  [20] ig_brr_filter — Enable ig_brr_filter in port 0
0x1B3A0 rio_tlm_sp_brr_0_ctl — (1 of 4, stride 128)
  [31] enable — Enable the base routing register
  [26] route_mr_to_llm — Route MR to LLM when set
  [24] private — Configures BRR to be used by its port or all ports
{0x1B3A4+0x10*i} rio_tlm_sp_brr_{i}_pattern_match (i=0..3) — (1 of 4, stride 128)
  [31:16] pattern — 16 bits that are compared against the inbound dest ID
  [15:0] match — 16 bits of inbound dest ID compared against pattern
{0x1B3A0+0x10*i} rio_tlm_sp_brr_{i}_ctl (i=1..3) — (1 of 4, stride 128)
  [31] enable — Enable the base routing register
  [26] route_mr_to_llm — Route BRR to LLM when set
  [24] private — Configures BRR to be used by its port or all ports
0x1B600 rio_pbm_bh ro
  fields as rio_plm_bh
0x1B680 rio_pbm_sp_control — (1 of 4, stride 128)
  [5:4] eg_reorder_mode — Selects the reorder action
  [2:0] eg_reorder_stick — Selects the number of repeat times the CRQ is reordered after each reorder event
0x1B690 rio_pbm_sp_status access per field — (1 of 4, stride 128)
  [16] ig_empty ro — The PBMi has no packets enqueued
  [15] eg_empty ro — The PBMe has no packets enqueued
  [4] eg_data_overflow wo
  [3] eg_crq_overflow wo
  [1] eg_bad_channel wo — PBMe received a request to enqueue a packet on a channel enqueue interface which should be unused for the path's mode
  [0] eg_babble_packet wo — PBMe detected a packet that exceeded 276 bytes on its enqueue interface
0x1B694 rio_pbm_sp_int_enable — (1 of 4, stride 128)
  [4] eg_data_overflow — Enable eg_data_overflow to contribute to ports IRQ
  [3] eg_crq_overflow — Enable eg_crq_overflow to contribute to ports IRQ
  [1] eg_bad_channel — Enable eg_bad_channel to contribute to ports IRQ
  [0] eg_babble_packet — Enable eg_babble_packet to contribute to ports IRQ
0x1B698 rio_pbm_sp_pw_enable — (1 of 4, stride 128)
  [4] eg_data_overflow — Enable eg_data_overflow to contribute to port-write
  [3] eg_crq_overflow — Enable eg_crq_overflow to contribute to port-write
  [1] eg_bad_channel — Enable eg_bad_channel to contribute to port-write
  [0] eg_babble_packet — Enable eg_babble_packet to contribute to port-write
0x1B69C rio_pbm_sp_event_gen — (1 of 4, stride 128)
  [4] eg_data_overflow — Enable eg_data_overflow in port 0
  [3] eg_crq_overflow — Enable eg_crq_overflow in port 0
  [1] eg_bad_channel — Enable eg_bad_channel in port 0
  [0] eg_babble_packet — Enable eg_babble_packet in port 0
0x1B6A0 rio_pbm_sp_ig_resources ro — (1 of 4, stride 128)
  [25:16] datanodes — Number of data nodes implemented in PBMi
  [9:0] tags — Number of tags implemented in PBMi
0x1B6A4 rio_pbm_sp_eg_resources ro — (1 of 4, stride 128)
  [25:16] datanodes — Number of data nodes implemented in PBMe
  [6:0] crq_entries — Number of crq entries implemented in PBMe
{0x1B6B0+4i} rio_pbm_sp_ig_watermark{i} (i=0..3) — (1 of 4, stride 128)
  [25:16] prio{i}crf_wm — Priority {i} CRF watermarks
  [9:0] prio{i}_wm — Priority {i} watermarks
0x1B900 rio_em_bh ro
  [31:16] next_blk_ptr — Pointer to the next register block
  [15:12] blk_rev — Tundra defined revision of the block type
  [11:0] blk_type — Tundra defined identifier for register block type
0x1B910 rio_em_int_stat ro
  [29] port — Port-specific event detected
  [28] log — Logical layer event detected
  [27] rcs — Reset request detected
  [26] mecs — A MECS with an enabled cmd field received
  [16] pw_rx — Port-write received
  [8] localog — Implementation-specific Logical/Transport layer error
0x1B914 rio_em_int_enable
  [28] log — Enable logical layer event to cause interrupt
  [26] mecs — Enables an interrupt to be raised upon reception of an MECS
  [16] pw_rx — Enables the reception of a port-write to cause an interrupt
  [8] localog — Enables an implementation-specific Logical/Transport Layer Error to cause an interrupt
0x1B918 rio_em_int_port_stat ro
  [3:0] irq_pending — Per-port interrupt pending status
0x1B920 rio_em_pw_stat ro
  [29] port — Port-specific event detected
  [28] log — Logical layer event detected
  [27] rcs — Reset request detected
  [9] multiport_err — Multiple ports have detected errors which use port-write notification
  [8] localog — Implementation-specific local Logical/Transport Layer Error
0x1B924 rio_em_pw_en
  [28] log — Enable logical layer event sends port-write when set
  [8] localog — Enables an implementation-specific Logical/Transport Layer Error to cause a port-write to be sent
0x1B928 rio_em_pw_port_stat ro
  [3:0] pw_pending — Per-port port-write pending status
0x1B930 rio_em_dev_int_en
  [0] int_en — Controls whether the device interrupt line can be asserted
0x1B934 rio_em_dev_pw_en
  [0] pw_en — Enable port-write
0x1B93C rio_em_mecs_stat wo
  [7:0] cmd_stat — MECS command status
0x1B940 rio_em_mecs_int_en
  [7:0] cmd_en — Enables MECS with set cmd to raise an interrupt request
0x1B944 rio_em_mecs_cap_en
  [7:0] cmd_en — Enables the associated bit of mecs_captured_out to toggle
0x1B948 rio_em_mecs_trig_en access per field
  [15:8] cmd_stat wo — A bit is set whenever an edge is detected on corresponding mecs_trigger_in pin
  [7:0] cmd_en rw — Enables the associated bit of mecs_trigger_in to trigger a MECS request to all SRIO ports
0x1B94C rio_em_mecs_req
  [8] send — Initiates a MECS request for each cmd value that is set in the CMD field
  [7:0] cmd — Indicates which MECS commands to be requested
0x1B950 rio_em_mecs_port_stat wo
  [3:0] port — MECS received status
0x1B95C rio_em_mecs_event_gen
  [7:0] cmd_stat — MECS event generation
0x1B960 rio_em_rst_port_stat wo
  [7:0] rst_req — Per-port reset control symbol event received status
0x1B968 rio_em_rst_int_en
  [3:0] rst_int_en — Per-port reset request event interrupt enable
0x1B970 rio_em_rst_pw_en
  [3:0] rst_pw_en — Per-port reset request port-write enable
0x1BA00 rio_pw_bh ro
  fields as rio_em_bh
0x1BA04 rio_pw_ctl
  [31:28] pw_timer — Port-write timer
  [24] pwc_mode — Port-write capture mode
0x1BA08 rio_pw_route
  [3:0] port — Indicates if a port-write should be sent to this port
0x1BA10 rio_pw_rx_stat access per field
  [15:12] wr_size rw — Port-write maximum size
  [8] wdptr rw — Port-write maximum size
  [3] pw_short rw — Port-write short
  [2] pw_trunc rw — Port-write truncation
  [1] pw_disc wo — Port-write discarded
  [0] pw_val wo — Port-write data registers contain valid data
0x1BA14 rio_pw_rx_event_gen
  [1] pw_disc — Port-write discarded
  [0] pw_val — Port-write data registers contain valid data
0x1BA20 rio_pw_rx_capt — (1 of 4, stride 4)
  [31:0] pw_capt — Port-write payload
0x1BD00 rio_llm_bh ro
  fields as rio_em_bh
0x1BD24 rio_whiteboard
  [31:0] scratch — May be read and written with any value
0x1BD28 rio_port_number ro
  [15:8] port_total
  [7:0] port_num — Port number
0x1BD30 rio_prescalar_srv_clk
  [7:0] prescalar_srv_clk — RIO prescalar srv_clk
0x1BD34 rio_reg_rst_ctl
  [0] clear_sticky — Allow self_rst and pwdn_port to clear sticky register bits
0x1BD48 rio_local_err_det
  [26] ill_id — Illegal transaction target error
  [22] ill_type — Unsupported transaction
0x1BD4C rio_local_err_en
  [26] ill_id_en — Enable reporting of illegal transaction target errors
  [22] ill_type_en — Enable reporting of unsupported transaction error enable
0x1BD50 rio_local_h_addr_capt
  [31:0] addr — Most significant bits of address associated with the error
0x1BD54 rio_local_addr_capt
  [31:3] addr — Least significant 29 bits of address associated with the error
  [1:0] xamsbs — Extended address bits of the address associated with the error
0x1BD58 rio_local_id_capt
  [31:24] msb_dest_id — Most significant byte of destID associated with the error
  [23:16] dest_id — destID associated with the error
  [15:8] msb_src_id — Most significant byte of srcID associated with the error
  [7:0] src_id — srcID associated with the error
0x1BD5C rio_local_ctrl_capt
  [31:28] ftype — FType associated with the error
  [27:24] ttype — TType associated with the error
  [23:16] message_info — Message information
0x1BE00 rio_fabric_bh ro
  fields as rio_em_bh
0x1BE10 rio_fabric_csr ro
  [27] ig_llm_backpressure — Ingress LLM backpressure indication
  [26] ig_uc_backpressure — Ingress user core backpressure indication
0x1BE40 rio_sp_fabric_status ro — (1 of 4, stride 4)
  [23:20] ig_pkt_enable_status — PBMi packet enable indication
  [19:16] eg_pkt_enable_status — PBMe packet enable indication
